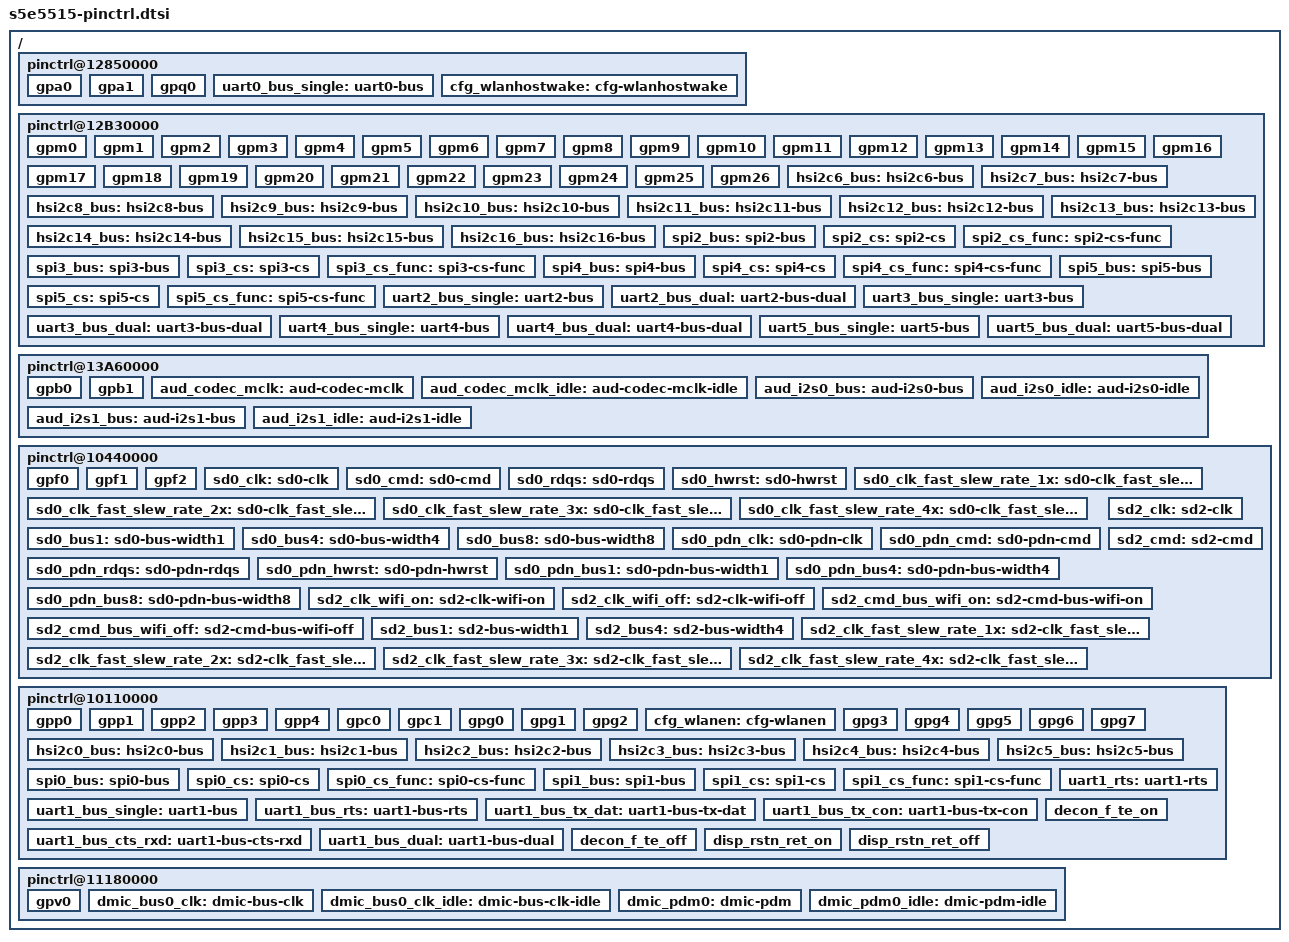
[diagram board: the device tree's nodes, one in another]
/*
 * Samsung's Exynos5515 SoC pin-mux and pin-config device tree source
 *
 * Copyright (c) 2017 Samsung Electronics Co., Ltd.
 *		http://www.samsung.com
 *
 * Samsung's Exynos5515 SoC pin-mux and pin-config options are listed as device
 * tree nodes are listed in this file.
 *
 * This program is free software; you can redistribute it and/or modify
 * it under the terms of the GNU General Public License version 2 as
 * published by the Free Software Foundation.
 */

/ {
	/* ALIVE */
	pinctrl@12850000 {
		gpa0: gpa0 {
			gpio-controller;
			#gpio-cells = <2>;

			interrupt-controller;
			#interrupt-cells = <3>;
			interrupt-parent = <&gic>;
			interrupts = <0 INTREQ__ALIVE_EXT_INT0 IRQ_TYPE_LEVEL_HIGH>,
						<0 INTREQ__ALIVE_EXT_INT1 IRQ_TYPE_LEVEL_HIGH>,
						<0 INTREQ__ALIVE_EXT_INT2 IRQ_TYPE_LEVEL_HIGH>,
						<0 INTREQ__ALIVE_EXT_INT3 IRQ_TYPE_LEVEL_HIGH>,
						<0 INTREQ__ALIVE_EXT_INT4 IRQ_TYPE_LEVEL_HIGH>,
						<0 INTREQ__ALIVE_EXT_INT5 IRQ_TYPE_LEVEL_HIGH>,
						<0 INTREQ__ALIVE_EXT_INT6 IRQ_TYPE_LEVEL_HIGH>,
						<0 INTREQ__ALIVE_EXT_INT7 IRQ_TYPE_LEVEL_HIGH>;
		};

		gpa1: gpa1 {
			gpio-controller;
			#gpio-cells = <2>;

			interrupt-controller;
			#interrupt-cells = <3>;
			interrupt-parent = <&gic>;
			interrupts = <0 INTREQ__ALIVE_EXT_INT8 IRQ_TYPE_LEVEL_HIGH>,
						<0 INTREQ__ALIVE_EXT_INT9 IRQ_TYPE_LEVEL_HIGH>,
						<0 INTREQ__ALIVE_EXT_INT10 IRQ_TYPE_LEVEL_HIGH>,
						<0 INTREQ__ALIVE_EXT_INT11 IRQ_TYPE_LEVEL_HIGH>,
						<0 INTREQ__ALIVE_EXT_INT12 IRQ_TYPE_LEVEL_HIGH>,
						<0 INTREQ__ALIVE_EXT_INT13 IRQ_TYPE_LEVEL_HIGH>,
						<0 INTREQ__ALIVE_EXT_INT14 IRQ_TYPE_LEVEL_HIGH>;
		};

		gpq0: gpq0 {
			gpio-controller;
			#gpio-cells = <2>;

			interrupt-controller;
			#interrupt-cells = <2>;
		};

		/* UART_DEBUG_0 */
		uart0_bus_single: uart0-bus {
			samsung,pins = "gpq0-0", "gpq0-1";
			samsung,pin-function = <2>;
			samsung,pin-pud = <3>;
		};

		/* WLAN_HOST_WAKE */
		cfg_wlanhostwake: cfg-wlanhostwake {
			samsung,pins = "gpa1-1";
			samsung,pin-function = <0xf>;  /* EXT INT */
			samsung,pin-pud = <1>;
			samsung,pin-con-pdn = <3>;
			samsung,pin-pud-pdn = <1>;
		}; 
	};

	/* CMGP_ALIVE */
	pinctrl@12B30000{
		gpm0: gpm0 {
			gpio-controller;
			#gpio-cells = <2>;

			interrupt-controller;
			#interrupt-cells = <3>;
			interrupt-parent = <&gic>;
			interrupts = <0 INTREQ__CMGP_EXT_INTM00 IRQ_TYPE_LEVEL_HIGH>;
		};

		gpm1: gpm1 {
			gpio-controller;
			#gpio-cells = <2>;

			interrupt-controller;
			#interrupt-cells = <3>;
			interrupt-parent = <&gic>;
			interrupts = <0 INTREQ__CMGP_EXT_INTM01 IRQ_TYPE_LEVEL_HIGH>;
		};

		gpm2: gpm2 {
			gpio-controller;
			#gpio-cells = <2>;

			interrupt-controller;
			#interrupt-cells = <3>;
			interrupt-parent = <&gic>;
			interrupts = <0 INTREQ__CMGP_EXT_INTM02 IRQ_TYPE_LEVEL_HIGH>;
		};

		gpm3: gpm3 {
			gpio-controller;
			#gpio-cells = <2>;

			interrupt-controller;
			#interrupt-cells = <3>;
			interrupt-parent = <&gic>;
			interrupts = <0 INTREQ__CMGP_EXT_INTM03 IRQ_TYPE_LEVEL_HIGH>;
		};

		gpm4: gpm4 {
			gpio-controller;
			#gpio-cells = <2>;

			interrupt-controller;
			#interrupt-cells = <3>;
			interrupt-parent = <&gic>;
			interrupts = <0 INTREQ__CMGP_EXT_INTM04 IRQ_TYPE_LEVEL_HIGH>;
		};

		gpm5: gpm5 {
			gpio-controller;
			#gpio-cells = <2>;

			interrupt-controller;
			#interrupt-cells = <3>;
			interrupt-parent = <&gic>;
			interrupts = <0 INTREQ__CMGP_EXT_INTM05 IRQ_TYPE_LEVEL_HIGH>;
		};

		gpm6: gpm6 {
			gpio-controller;
			#gpio-cells = <2>;

			interrupt-controller;
			#interrupt-cells = <3>;
			interrupt-parent = <&gic>;
			interrupts = <0 INTREQ__CMGP_EXT_INTM06 IRQ_TYPE_LEVEL_HIGH>;
		};

		gpm7: gpm7 {
			gpio-controller;
			#gpio-cells = <2>;

			interrupt-controller;
			#interrupt-cells = <3>;
			interrupt-parent = <&gic>;
			interrupts = <0 INTREQ__CMGP_EXT_INTM07 IRQ_TYPE_LEVEL_HIGH>;
		};

		gpm8: gpm8 {
			gpio-controller;
			#gpio-cells = <2>;

			interrupt-controller;
			#interrupt-cells = <3>;
			interrupt-parent = <&gic>;
			interrupts = <0 INTREQ__CMGP_EXT_INTM08 IRQ_TYPE_LEVEL_HIGH>;
		};

		gpm9: gpm9 {
			gpio-controller;
			#gpio-cells = <2>;

			interrupt-controller;
			#interrupt-cells = <3>;
			interrupt-parent = <&gic>;
			interrupts = <0 INTREQ__CMGP_EXT_INTM09 IRQ_TYPE_LEVEL_HIGH>;
		};

		gpm10: gpm10 {
			gpio-controller;
			#gpio-cells = <2>;

			interrupt-controller;
			#interrupt-cells = <3>;
			interrupt-parent = <&gic>;
			interrupts = <0 INTREQ__CMGP_EXT_INTM10 IRQ_TYPE_LEVEL_HIGH>;
		};

		gpm11: gpm11 {
			gpio-controller;
			#gpio-cells = <2>;

			interrupt-controller;
			#interrupt-cells = <3>;
			interrupt-parent = <&gic>;
			interrupts = <0 INTREQ__CMGP_EXT_INTM11 IRQ_TYPE_LEVEL_HIGH>;
		};

		gpm12: gpm12 {
			gpio-controller;
			#gpio-cells = <2>;

			interrupt-controller;
			#interrupt-cells = <3>;
			interrupt-parent = <&gic>;
			interrupts = <0 INTREQ__CMGP_EXT_INTM12 IRQ_TYPE_LEVEL_HIGH>;
		};

		gpm13: gpm13 {
			gpio-controller;
			#gpio-cells = <2>;

			interrupt-controller;
			#interrupt-cells = <3>;
			interrupt-parent = <&gic>;
			interrupts = <0 INTREQ__CMGP_EXT_INTM13 IRQ_TYPE_LEVEL_HIGH>;
		};

		gpm14: gpm14 {
			gpio-controller;
			#gpio-cells = <2>;

			interrupt-controller;
			#interrupt-cells = <3>;
			interrupt-parent = <&gic>;
			interrupts = <0 INTREQ__CMGP_EXT_INTM14 IRQ_TYPE_LEVEL_HIGH>;
		};

		gpm15: gpm15 {
			gpio-controller;
			#gpio-cells = <2>;

			interrupt-controller;
			#interrupt-cells = <3>;
			interrupt-parent = <&gic>;
			interrupts = <0 INTREQ__CMGP_EXT_INTM15 IRQ_TYPE_LEVEL_HIGH>;
		};

		gpm16: gpm16 {
			gpio-controller;
			#gpio-cells = <2>;

			interrupt-controller;
			#interrupt-cells = <3>;
			interrupt-parent = <&gic>;
			interrupts = <0 INTREQ__CMGP_EXT_INTM16 IRQ_TYPE_LEVEL_HIGH>;
		};

		gpm17: gpm17 {
			gpio-controller;
			#gpio-cells = <2>;

			interrupt-controller;
			#interrupt-cells = <3>;
			interrupt-parent = <&gic>;
			interrupts = <0 INTREQ__CMGP_EXT_INTM17 IRQ_TYPE_LEVEL_HIGH>;
		};

		gpm18: gpm18 {
			gpio-controller;
			#gpio-cells = <2>;

			interrupt-controller;
			#interrupt-cells = <3>;
			interrupt-parent = <&gic>;
			interrupts = <0 INTREQ__CMGP_EXT_INTM18 IRQ_TYPE_LEVEL_HIGH>;
		};

		gpm19: gpm19 {
			gpio-controller;
			#gpio-cells = <2>;

			interrupt-controller;
			#interrupt-cells = <3>;
			interrupt-parent = <&gic>;
			interrupts = <0 INTREQ__CMGP_EXT_INTM19 IRQ_TYPE_LEVEL_HIGH>;
		};

		gpm20: gpm20 {
			gpio-controller;
			#gpio-cells = <2>;

			interrupt-controller;
			#interrupt-cells = <3>;
			interrupt-parent = <&gic>;
			interrupts = <0 INTREQ__CMGP_EXT_INTM20 IRQ_TYPE_LEVEL_HIGH>;
		};

		gpm21: gpm21 {
			gpio-controller;
			#gpio-cells = <2>;

			interrupt-controller;
			#interrupt-cells = <3>;
			interrupt-parent = <&gic>;
			interrupts = <0 INTREQ__CMGP_EXT_INTM21 IRQ_TYPE_LEVEL_HIGH>;
		};

		gpm22: gpm22 {
			gpio-controller;
			#gpio-cells = <2>;

			interrupt-controller;
			#interrupt-cells = <3>;
			interrupt-parent = <&gic>;
			interrupts = <0 INTREQ__CMGP_EXT_INTM22 IRQ_TYPE_LEVEL_HIGH>;
		};

		gpm23: gpm23 {
			gpio-controller;
			#gpio-cells = <2>;

			interrupt-controller;
			#interrupt-cells = <3>;
			interrupt-parent = <&gic>;
			interrupts = <0 INTREQ__CMGP_EXT_INTM23 IRQ_TYPE_LEVEL_HIGH>;
		};

		gpm24: gpm24 {
			gpio-controller;
			#gpio-cells = <2>;

			interrupt-controller;
			#interrupt-cells = <3>;
			interrupt-parent = <&gic>;
			interrupts = <0 INTREQ__CMGP_EXT_INTM24 IRQ_TYPE_LEVEL_HIGH>;
		};

		gpm25: gpm25 {
			gpio-controller;
			#gpio-cells = <2>;

			interrupt-controller;
			#interrupt-cells = <3>;
			interrupt-parent = <&gic>;
			interrupts = <0 INTREQ__CMGP_EXT_INTM25 IRQ_TYPE_LEVEL_HIGH>;
		};

		gpm26: gpm26 {
			gpio-controller;
			#gpio-cells = <2>;

			interrupt-controller;
			#interrupt-cells = <3>;
			interrupt-parent = <&gic>;
			interrupts = <0 INTREQ__CMGP_EXT_INTM26 IRQ_TYPE_LEVEL_HIGH>;
		};

		/* usi_cmgp00 */
		hsi2c6_bus: hsi2c6-bus {
			samsung,pins = "gpm0-0", "gpm1-0";
			samsung,pin-function = <2>;
			samsung,pin-pud = <3>;
			samsung,pin-drv = <0>;
		};

		/* usi_cmgp00_i2c */
		hsi2c7_bus: hsi2c7-bus {
			samsung,pins = "gpm2-0", "gpm3-0";
			samsung,pin-function = <3>;
			samsung,pin-pud = <3>;
			samsung,pin-drv = <0>;
		};

		/* usi_cmgp01 */
		hsi2c8_bus: hsi2c8-bus {
			samsung,pins = "gpm4-0", "gpm5-0";
			samsung,pin-function = <2>;
			samsung,pin-pud = <3>;
			samsung,pin-drv = <0>;
		};

		/* usi_cmgp01_i2c */
		hsi2c9_bus: hsi2c9-bus {
			samsung,pins = "gpm6-0", "gpm7-0";
			samsung,pin-function = <3>;
			samsung,pin-pud = <3>;
			samsung,pin-drv = <0>;
		};

		/* usi_cmgp02 */
		hsi2c10_bus: hsi2c10-bus {
			samsung,pins = "gpm8-0", "gpm9-0";
			samsung,pin-function = <2>;
			samsung,pin-pud = <3>;
			samsung,pin-drv = <0>;
		};

		/* usi_cmgp02_i2c */
		hsi2c11_bus: hsi2c11-bus {
			samsung,pins = "gpm10-0", "gpm11-0";
			samsung,pin-function = <3>;
			samsung,pin-pud = <3>;
			samsung,pin-drv = <0>;
		};

		/* usi_cmgp03 */
		hsi2c12_bus: hsi2c12-bus {
			samsung,pins = "gpm12-0", "gpm13-0";
			samsung,pin-function = <2>;
			samsung,pin-pud = <3>;
			samsung,pin-drv = <0>;
		};

		/* usi_cmgp03_i2c */
		hsi2c13_bus: hsi2c13-bus {
			samsung,pins = "gpm14-0", "gpm15-0";
			samsung,pin-function = <3>;
			samsung,pin-pud = <3>;
			samsung,pin-drv = <0>;
		};

		/* usi_cmgp04_i2c */
		hsi2c14_bus: hsi2c14-bus {
			samsung,pins = "gpm16-0", "gpm17-0";
			samsung,pin-function = <2>;
			samsung,pin-pud = <3>;
			samsung,pin-drv = <0>;
		};

		/* usi_cmgp05_i2c */
		hsi2c15_bus: hsi2c15-bus {
			samsung,pins = "gpm18-0", "gpm19-0";
			samsung,pin-function = <2>;
			samsung,pin-pud = <3>;
			samsung,pin-drv = <0>;
		};

		/* usi_cmgp06_i2c */
		hsi2c16_bus: hsi2c16-bus {
			samsung,pins = "gpm20-0", "gpm21-0";
			samsung,pin-function = <2>;
			samsung,pin-pud = <3>;
			samsung,pin-drv = <0>;
		};

		/* usi_cmgp00 */
		spi2_bus: spi2-bus {
			samsung,pins = "gpm0-0", "gpm1-0", "gpm4-0";
			samsung,pin-function = <2>;
			samsung,pin-pud = <0>;
			samsung,pin-drv = <0>;
		};

		spi2_cs: spi2-cs {
			samsung,pins = "gpm3-0";
			samsung,pin-function = <1>;
			samsung,pin-pud = <0>;
			samsung,pin-drv = <0>;
		};

		spi2_cs_func: spi2-cs-func {
			samsung,pins = "gpm3-0";
			samsung,pin-function = <2>;
			samsung,pin-pud = <0>;
			samsung,pin-drv = <0>;
		};

		/* usi_cmgp01 */
		spi3_bus: spi3-bus {
			samsung,pins = "gpm4-0", "gpm5-0", "gpm6-0";
			samsung,pin-function = <2>;
			samsung,pin-pud = <0>;
			samsung,pin-drv = <0>;
		};

		spi3_cs: spi3-cs {
			samsung,pins = "gpm7-0";
			samsung,pin-function = <1>;
			samsung,pin-pud = <0>;
			samsung,pin-drv = <0>;
		};

		spi3_cs_func: spi3-cs-func {
			samsung,pins = "gpm7-0";
			samsung,pin-function = <2>;
			samsung,pin-pud = <0>;
			samsung,pin-drv = <0>;
		};

		/* usi_cmgp02 */
		spi4_bus: spi4-bus {
			samsung,pins = "gpm8-0", "gpm9-0", "gpm10-0";
			samsung,pin-function = <2>;
			samsung,pin-pud = <0>;
			samsung,pin-drv = <0>;
		};

		spi4_cs: spi4-cs {
			samsung,pins = "gpm11-0";
			samsung,pin-function = <1>;
			samsung,pin-pud = <0>;
			samsung,pin-drv = <0>;
		};

		spi4_cs_func: spi4-cs-func {
			samsung,pins = "gpm11-0";
			samsung,pin-function = <2>;
			samsung,pin-pud = <0>;
			samsung,pin-drv = <0>;
		};

		/* usi_cmgp03 */
		spi5_bus: spi5-bus {
			samsung,pins = "gpm12-0", "gpm13-0", "gpm14-0";
			samsung,pin-function = <2>;
			samsung,pin-pud = <0>;
			samsung,pin-drv = <0>;
		};

		spi5_cs: spi5-cs {
			samsung,pins = "gpm15-0";
			samsung,pin-function = <1>;
			samsung,pin-pud = <0>;
			samsung,pin-drv = <0>;
		};

		spi5_cs_func: spi5-cs-func {
			samsung,pins = "gpm15-0";
			samsung,pin-function = <2>;
			samsung,pin-pud = <0>;
			samsung,pin-drv = <0>;
		};

		/* usi_cmgp00_uart */
		uart2_bus_single: uart2-bus {
			samsung,pins = "gpm0-0", "gpm1-0", "gpm2-0", "gpm3-0";
			samsung,pin-function = <2>;
			samsung,pin-pud = <0>;
		};

		uart2_bus_dual: uart2-bus-dual {
			samsung,pins = "gpm0-0", "gpm1-0";
			samsung,pin-function = <2>;
			samsung,pin-pud = <0>;
		};

		/* usi_cmgp01_uart */
		uart3_bus_single: uart3-bus {
			samsung,pins = "gpm4-0", "gpm5-0", "gpm6-0", "gpm7-0";
			samsung,pin-function = <2>;
			samsung,pin-pud = <0>;
		};

		uart3_bus_dual: uart3-bus-dual {
			samsung,pins = "gpm4-0", "gpm5-0";
			samsung,pin-function = <2>;
			samsung,pin-pud = <0>;
		};

		/* usi_cmgp02_uart */
		uart4_bus_single: uart4-bus {
			samsung,pins = "gpm8-0", "gpm9-0", "gpm10-0", "gpm11-0";
			samsung,pin-function = <2>;
			samsung,pin-pud = <0>;
		};

		uart4_bus_dual: uart4-bus-dual {
			samsung,pins = "gpm8-0", "gpm9-0";
			samsung,pin-function = <2>;
			samsung,pin-pud = <0>;
		};

		/* usi_cmgp03_uart */
		uart5_bus_single: uart5-bus {
			samsung,pins = "gpm12-0", "gpm13-0", "gpm14-0", "gpm15-0";
			samsung,pin-function = <2>;
			samsung,pin-pud = <0>;
		};

		uart5_bus_dual: uart5-bus-dual {
			samsung,pins = "gpm12-0", "gpm13-0";
			samsung,pin-function = <2>;
			samsung,pin-pud = <0>;
		};
	};

	/* DPU */
	pinctrl@13A60000 {
		gpb0: gpb0 {
			gpio-controller;
			#gpio-cells = <2>;

			interrupt-controller;
			#interrupt-cells = <3>;
			interrupt-parent = <&gic>;
			interrupts = <0 INTREQ__DPU_DECON0_EXTRA IRQ_TYPE_LEVEL_HIGH>,
						<0 INTREQ__DPU_DECON0_FRAME_DONE IRQ_TYPE_LEVEL_HIGH>,
						<0 INTREQ__DPU_DECON0_FRAME_START IRQ_TYPE_LEVEL_HIGH>,
						<0 INTREQ__DPU_DMA_G0 IRQ_TYPE_LEVEL_HIGH>,
						<0 INTREQ__DPU_DMA_G1 IRQ_TYPE_LEVEL_HIGH>;
		};

		gpb1: gpb1 {
			gpio-controller;
			#gpio-cells = <2>;

			interrupt-controller;
			#interrupt-cells = <3>;
			interrupt-parent = <&gic>;
			interrupts = <0 INTREQ__DPU_DMA_VG IRQ_TYPE_LEVEL_HIGH>,
						<0 INTREQ__DPU_DPP_G0 IRQ_TYPE_LEVEL_HIGH>,
						<0 INTREQ__DPU_DPP_G1 IRQ_TYPE_LEVEL_HIGH>,
						<0 INTREQ__DPU_DPP_VG IRQ_TYPE_LEVEL_HIGH>,
						<0 INTREQ__DPU_DSIM0 IRQ_TYPE_LEVEL_HIGH>;
		};

		aud_codec_mclk: aud-codec-mclk {
			samsung,pins = "gpb0-0";
			samsung,pin-function = <2>;
			samsung,pin-pud = <1>;
		};

		aud_codec_mclk_idle: aud-codec-mclk-idle {
			samsung,pins = "gpb0-0";
			samsung,pin-function = <2>;
			samsung,pin-pud = <1>;
		};

		aud_i2s0_bus: aud-i2s0-bus {
			samsung,pins = "gpb0-1", "gpb0-2", "gpb0-3", "gpb0-4";
			samsung,pin-function = <2>;
			samsung,pin-pud = <1>;
		};

		aud_i2s0_idle: aud-i2s0-idle {
			samsung,pins = "gpb0-1", "gpb0-2", "gpb0-3", "gpb0-4";
			samsung,pin-function = <0>;
			samsung,pin-pud = <1>;
		};

		aud_i2s1_bus: aud-i2s1-bus {
			samsung,pins = "gpb1-0", "gpb1-1", "gpb1-2", "gpb1-3";
			samsung,pin-function = <2>;
			samsung,pin-pud = <1>;
		};

		aud_i2s1_idle: aud-i2s1-idle {
			samsung,pins = "gpb1-0", "gpb1-1", "gpb1-2", "gpb1-3";
			samsung,pin-function = <0>;
			samsung,pin-pud = <1>;
		};
/*
		aud_fm_bus: aud-fm-bus {
			samsung,pins = "gpb1-4";
			samsung,pin-function = <2>;
			samsung,pin-pud = <1>;
		};

		aud_fm_idle: aud-fm-idle {
			samsung,pins = "gpb1-4";
			samsung,pin-function = <0>;
			samsung,pin-pud = <1>;
		};
*/
	};

	/* FSYS */
	pinctrl@10440000 {
		gpf0: gpf0 {
			gpio-controller;
			#gpio-cells = <2>;

			interrupt-controller;
			#interrupt-cells = <2>;
		};
		gpf1: gpf1 {
			gpio-controller;
			#gpio-cells = <2>;

			interrupt-controller;
			#interrupt-cells = <2>;
		};
		gpf2: gpf2 {
			gpio-controller;
			#gpio-cells = <2>;

			interrupt-controller;
			#interrupt-cells = <2>;
		};

		sd0_clk: sd0-clk {
			samsung,pins = "gpf0-0";
			samsung,pin-function = <2>;
			samsung,pin-pud = <0>;
			samsung,pin-drv = <3>;
		};

		sd0_cmd: sd0-cmd {
			samsung,pins = "gpf0-1";
			samsung,pin-function = <2>;
			samsung,pin-pud = <0>;
			samsung,pin-drv = <3>;
		};

		sd0_rdqs: sd0-rdqs {
			samsung,pins = "gpf0-2";
			samsung,pin-function = <2>;
			samsung,pin-pud = <1>;
			samsung,pin-drv = <3>;
		};

		sd0_hwrst: sd0-hwrst {
			samsung,pins = "gpf0-3";
			samsung,pin-function = <2>;
			samsung,pin-pud = <0>;
			samsung,pin-drv = <3>;
		};

		sd0_clk_fast_slew_rate_1x: sd0-clk_fast_slew_rate_1x {
			samsung,pins = "gpf0-0";
			samsung,pin-function = <2>;
			samsung,pin-pud = <0>;
			samsung,pin-drv = <0>;
		};

		sd0_clk_fast_slew_rate_2x: sd0-clk_fast_slew_rate_2x {
			samsung,pins = "gpf0-0";
			samsung,pin-function = <2>;
			samsung,pin-pud = <0>;
			samsung,pin-drv = <1>;
		};

		sd0_clk_fast_slew_rate_3x: sd0-clk_fast_slew_rate_3x {
			samsung,pins = "gpf0-0";
			samsung,pin-function = <2>;
			samsung,pin-pud = <0>;
			samsung,pin-drv = <2>;
		};

		sd0_clk_fast_slew_rate_4x: sd0-clk_fast_slew_rate_4x {
			samsung,pins = "gpf0-0";
			samsung,pin-function = <2>;
			samsung,pin-pud = <0>;
			samsung,pin-drv = <3>;
		};

		sd0_bus1: sd0-bus-width1 {
			samsung,pins = "gpf1-0";
			samsung,pin-function = <2>;
			samsung,pin-pud = <3>;
			samsung,pin-drv = <3>;
		};

		sd0_bus4: sd0-bus-width4 {
			samsung,pins = "gpf1-1", "gpf1-2", "gpf1-3";
			samsung,pin-function = <2>;
			samsung,pin-pud = <3>;
			samsung,pin-drv = <3>;
		};

		sd0_bus8: sd0-bus-width8 {
			samsung,pins = "gpf1-4", "gpf1-5", "gpf1-6", "gpf1-7";
			samsung,pin-function = <2>;
			samsung,pin-pud = <3>;
			samsung,pin-drv = <3>;
		};

		sd0_pdn_clk: sd0-pdn-clk {
			samsung,pins = "gpf0-0";
			samsung,pin-function = <1>;
			samsung,pin-pud = <1>;
		};

		sd0_pdn_cmd: sd0-pdn-cmd {
			samsung,pins = "gpf0-1";
			samsung,pin-function = <1>;
			samsung,pin-pud = <1>;
		};

		sd0_pdn_rdqs: sd0-pdn-rdqs {
			samsung,pins = "gpf0-2";
			samsung,pin-function = <1>;
			samsung,pin-pud = <1>;
		};

		sd0_pdn_hwrst: sd0-pdn-hwrst {
			samsung,pins = "gpf0-3";
			samsung,pin-function = <1>;
			samsung,pin-pud = <1>;
		};

		sd0_pdn_bus1: sd0-pdn-bus-width1 {
			samsung,pins = "gpf1-0";
			samsung,pin-function = <1>;
			samsung,pin-pud = <1>;
		};

		sd0_pdn_bus4: sd0-pdn-bus-width4 {
			samsung,pins = "gpf1-1", "gpf1-2", "gpf1-3";
			samsung,pin-function = <1>;
			samsung,pin-pud = <1>;
		};

		sd0_pdn_bus8: sd0-pdn-bus-width8 {
			samsung,pins = "gpf1-4", "gpf1-5", "gpf1-6", "gpf1-7";
			samsung,pin-function = <1>;
			samsung,pin-pud = <1>;
		};

		sd2_clk: sd2-clk {
			samsung,pins = "gpf2-0";
			samsung,pin-function = <0>;
			samsung,pin-pud = <1>;
			samsung,pin-drv = <2>;
			samsung,pin-con-pdn = <2>;
			samsung,pin-pud-pdn = <1>;
		};

		sd2_cmd: sd2-cmd {
			samsung,pins = "gpf2-1";
			samsung,pin-function = <0>;
			samsung,pin-pud = <1>;
			samsung,pin-drv = <2>;
			samsung,pin-con-pdn = <2>;
			samsung,pin-pud-pdn = <1>;
		};

		sd2_clk_wifi_on: sd2-clk-wifi-on {
			samsung,pins = "gpf2-0";
			samsung,pin-function = <2>;
			samsung,pin-pud = <0>;
			samsung,pin-drv = <2>;
			samsung,pin-con-pdn = <0>;
			samsung,pin-pud-pdn = <1>;
		};

		sd2_clk_wifi_off: sd2-clk-wifi-off {
			samsung,pins = "gpf2-0";
			samsung,pin-function = <0>;
			samsung,pin-pud = <1>;
			samsung,pin-drv = <2>;
			samsung,pin-con-pdn = <2>;
			samsung,pin-pud-pdn = <1>;
		};

		sd2_cmd_bus_wifi_on: sd2-cmd-bus-wifi-on {
			samsung,pins = "gpf2-1", "gpf2-2", "gpf2-3", "gpf2-4", "gpf2-5";
			samsung,pin-function = <2>;
			samsung,pin-pud = <3>;
			samsung,pin-drv = <2>;
			samsung,pin-con-pdn = <2>;
			samsung,pin-pud-pdn = <3>;

		};

		sd2_cmd_bus_wifi_off: sd2-cmd-bus-wifi-off {
			samsung,pins = "gpf2-1", "gpf2-2", "gpf2-3", "gpf2-4", "gpf2-5";
			samsung,pin-function = <0>;
			samsung,pin-pud = <1>;
			samsung,pin-drv = <2>;
			samsung,pin-con-pdn = <2>;
			samsung,pin-pud-pdn = <1>;
		};

		sd2_bus1: sd2-bus-width1 {
			samsung,pins = "gpf2-2";
			samsung,pin-function = <0>;
			samsung,pin-pud = <1>;
			samsung,pin-drv = <2>;
			samsung,pin-con-pdn = <2>;
			samsung,pin-pud-pdn = <1>;
		};

		sd2_bus4: sd2-bus-width4 {
			samsung,pins = "gpf2-3", "gpf2-4", "gpf2-5";
			samsung,pin-function = <0>;
			samsung,pin-pud = <1>;
			samsung,pin-drv = <2>;
			samsung,pin-con-pdn = <2>;
			samsung,pin-pud-pdn = <1>;
		};

		sd2_clk_fast_slew_rate_1x: sd2-clk_fast_slew_rate_1x {
			samsung,pins = "gpf2-0";
			samsung,pin-function = <2>;
			samsung,pin-pud = <0>;
			samsung,pin-drv = <0>;
		};

		sd2_clk_fast_slew_rate_2x: sd2-clk_fast_slew_rate_2x {
			samsung,pins = "gpf2-0";
			samsung,pin-function = <2>;
			samsung,pin-pud = <0>;
			samsung,pin-drv = <1>;
		};

		sd2_clk_fast_slew_rate_3x: sd2-clk_fast_slew_rate_3x {
			samsung,pins = "gpf2-0";
			samsung,pin-function = <2>;
			samsung,pin-pud = <0>;
			samsung,pin-drv = <2>;
		};

		sd2_clk_fast_slew_rate_4x: sd2-clk_fast_slew_rate_4x {
			samsung,pins = "gpf2-0";
			samsung,pin-function = <2>;
			samsung,pin-pud = <0>;
			samsung,pin-drv = <3>;
		};
	};

	/* PERI */
	pinctrl@10110000 {
		gpp0: gpp0 {
			gpio-controller;
			#gpio-cells = <2>;

			interrupt-controller;
			#interrupt-cells = <2>;
		};

		gpp1: gpp1 {
			gpio-controller;
			#gpio-cells = <2>;

			interrupt-controller;
			#interrupt-cells = <2>;
		};

		gpp2: gpp2 {
			gpio-controller;
			#gpio-cells = <2>;

			interrupt-controller;
			#interrupt-cells = <2>;
		};

		gpp3: gpp3 {
			gpio-controller;
			#gpio-cells = <2>;

			interrupt-controller;
			#interrupt-cells = <2>;
		};

		gpp4: gpp4 {
			gpio-controller;
			#gpio-cells = <2>;

			interrupt-controller;
			#interrupt-cells = <2>;
		};

		gpc0: gpc0 {
			gpio-controller;
			#gpio-cells = <2>;

			interrupt-controller;
			#interrupt-cells = <2>;
		};

		gpc1: gpc1 {
			gpio-controller;
			#gpio-cells = <2>;

			interrupt-controller;
			#interrupt-cells = <2>;
		};

		gpg0: gpg0 {
			gpio-controller;
			#gpio-cells = <2>;

			interrupt-controller;
			#interrupt-cells = <2>;
		};

		gpg1: gpg1 {
			gpio-controller;
			#gpio-cells = <2>;

			interrupt-controller;
			#interrupt-cells = <2>;
		};

		gpg2: gpg2 {
			gpio-controller;
			#gpio-cells = <2>;

			interrupt-controller;
			#interrupt-cells = <2>;
		};

		cfg_wlanen: cfg-wlanen {
			samsung,pins = "gpg2-0";
			samsung,pin-function = <1>;
			samsung,pin-pud = <0>;
			samsung,pin-drv = <0>;
			samsung,pin-con-pdn = <3>;
			samsung,pin-pud-pdn = <0>;
			samsung,pin-val = <0>;
		};

		gpg3: gpg3 {
			gpio-controller;
			#gpio-cells = <2>;

			interrupt-controller;
			#interrupt-cells = <2>;
		};

		gpg4: gpg4 {
			gpio-controller;
			#gpio-cells = <2>;

			interrupt-controller;
			#interrupt-cells = <2>;
		};

		gpg5: gpg5 {
			gpio-controller;
			#gpio-cells = <2>;

			interrupt-controller;
			#interrupt-cells = <2>;
		};

		gpg6: gpg6 {
			gpio-controller;
			#gpio-cells = <2>;

			interrupt-controller;
			#interrupt-cells = <2>;
		};

		gpg7: gpg7 {
			gpio-controller;
			#gpio-cells = <2>;

			interrupt-controller;
			#interrupt-cells = <2>;
		};

		/* i2c_0 */
		hsi2c0_bus: hsi2c0-bus {
			samsung,pins = "gpp0-0", "gpp0-1";
			samsung,pin-function = <2>;
			samsung,pin-pud = <3>;
			samsung,pin-drv = <0>;
		};

		/* i2c_1 */
		hsi2c1_bus: hsi2c1-bus {
			samsung,pins = "gpp1-0", "gpp1-1";
			samsung,pin-function = <2>;
			samsung,pin-pud = <3>;
			samsung,pin-drv = <0>;
		};

		/* i2c_2 */
		hsi2c2_bus: hsi2c2-bus {
			samsung,pins = "gpp2-0", "gpp2-1";
			samsung,pin-function = <2>;
			samsung,pin-pud = <3>;
			samsung,pin-drv = <0>;
		};

		/* i2c_3 */
		hsi2c3_bus: hsi2c3-bus {
			samsung,pins = "gpp3-0", "gpp3-1";
			samsung,pin-function = <2>;
			samsung,pin-pud = <3>;
			samsung,pin-drv = <0>;
		};

		/* usi_usi */
		hsi2c4_bus: hsi2c4-bus {
			samsung,pins = "gpc0-0", "gpc0-1";
			samsung,pin-function = <2>;
			samsung,pin-pud = <3>;
			samsung,pin-drv = <0>;
		};

		/* usi_i2c0 */
		hsi2c5_bus: hsi2c5-bus {
			samsung,pins = "gpc0-2", "gpc0-3";
			samsung,pin-function = <3>;
			samsung,pin-pud = <3>;
			samsung,pin-drv = <0>;
		};

		/* usi_usi */
		spi0_bus: spi0-bus {
			samsung,pins = "gpc0-0", "gpc0-1", "gpc0-2";
			samsung,pin-function = <2>;
			samsung,pin-pud = <0>;
			samsung,pin-drv = <0>;
		};

		spi0_cs: spi0-cs {
			samsung,pins = "gpc0-3";
			samsung,pin-function = <1>;
			samsung,pin-pud = <0>;
			samsung,pin-drv = <0>;
		};

		spi0_cs_func: spi0-cs-func {
			samsung,pins = "gpc0-3";
			samsung,pin-function = <2>;
			samsung,pin-pud = <0>;
			samsung,pin-drv = <0>;
		};

		/* usi_spi */
		spi1_bus: spi1-bus {
			samsung,pins = "gpp4-0", "gpp4-1", "gpp4-2";
			samsung,pin-function = <2>;
			samsung,pin-pud = <0>;
			samsung,pin-drv = <0>;
		};

		spi1_cs: spi1-cs {
			samsung,pins = "gpp4-3";
			samsung,pin-function = <1>;
			samsung,pin-pud = <0>;
			samsung,pin-drv = <0>;
		};

		spi1_cs_func: spi1-cs-func {
			samsung,pins = "gpp4-3";
			samsung,pin-function = <2>;
			samsung,pin-pud = <0>;
			samsung,pin-drv = <0>;
		};

		/* usi_usi */
		uart1_bus_single: uart1-bus {
			samsung,pins = "gpc0-0", "gpc0-1", "gpc0-2", "gpc0-3";
			samsung,pin-function = <2>;
			samsung,pin-drv = <0>;
			samsung,pin-pud = <3>;
		};

		/* UART USI_00 */
		uart1_rts: uart1-rts {
			samsung,pins = "gpc0-2";
			samsung,pin-function = <2>;
			samsung,pin-pud = <3>;
			samsung,pin-pud-pdn = <0>;
		};

		/* UART bus rts */
		uart1_bus_rts: uart1-bus-rts {
			samsung,pins = "gpc0-2";
			samsung,pin-function = <1>;
			samsung,pin-pud = <0>;
			samsung,pin-val = <1>;
			samsung,pin-con-pdn = <1>;
			samsung,pin-pud-pdn = <3>;
		};

		/* UART bus tx_data */
		uart1_bus_tx_dat: uart1-bus-tx-dat {
			samsung,pins = "gpc0-1";
			samsung,pin-val = <1>;
		};

		/* UART bus tx_con */
		uart1_bus_tx_con: uart1-bus-tx-con {
			samsung,pins = "gpc0-1";
			samsung,pin-function = <1>;
			samsung,pin-con-pdn = <1>;
			samsung,pin-pud-pdn = <3>;
		};

		/* usi_usi00_cts_rxd */
		uart1_bus_cts_rxd: uart1-bus-cts-rxd {
			samsung,pins = "gpc0-0", "gpc0-3";
			samsung,pin-function = <2>;
			samsung,pin-pud = <3>;
			samsung,pin-con-pdn = <2>;
			samsung,pin-pud-pdn = <3>;
		};

		uart1_bus_dual: uart1-bus-dual {
			samsung,pins = "gpc0-0", "gpc0-1";
			samsung,pin-function = <2>;
			samsung,pin-pud = <0>;
		};

		decon_f_te_on: decon_f_te_on {
			samsung,pins = "gpc1-0";
			samsung,pin-function = <0xf>;
		};

		decon_f_te_off: decon_f_te_off {
			samsung,pins = "gpc1-0";
			samsung,pin-function = <0>;
		};

		disp_rstn_ret_on: disp_rstn_ret_on {
			samsung,pins = "gpg3-1";
			samsung,pin-con-pdn = <3>; /* Retention */
		};

		disp_rstn_ret_off: disp_rstn_ret_off {
			samsung,pins = "gpg3-1";
			samsung,pin-con-pdn = <0>; /* Restore original */
		};
	};

	/* VTS */
	pinctrl@11180000{
		gpv0: gpv0 {
			gpio-controller;
			#gpio-cells = <2>;

			interrupt-controller;
			#interrupt-cells = <2>;
		};

		dmic_bus0_clk: dmic-bus-clk {
			samsung,pins = "gpv0-1";
			samsung,pin-function = <2>;
			samsung,pin-pud = <1>;
			samsung,pin-con-pdn = <2>;
		};

		dmic_bus0_clk_idle: dmic-bus-clk-idle {
			samsung,pins = "gpv0-1";
			samsung,pin-function = <0>;
			samsung,pin-pud = <0>;
			samsung,pin-con-pdn = <2>;
		};

		dmic_pdm0: dmic-pdm {
			samsung,pins = "gpv0-0";
			samsung,pin-function = <2>;
			samsung,pin-pud = <1>;
			samsung,pin-con-pdn = <2>;
		};

		dmic_pdm0_idle: dmic-pdm-idle {
			samsung,pins = "gpv0-0";
			samsung,pin-function = <0>;
			samsung,pin-pud = <0>;
			samsung,pin-con-pdn = <2>;
		};
	};
};
